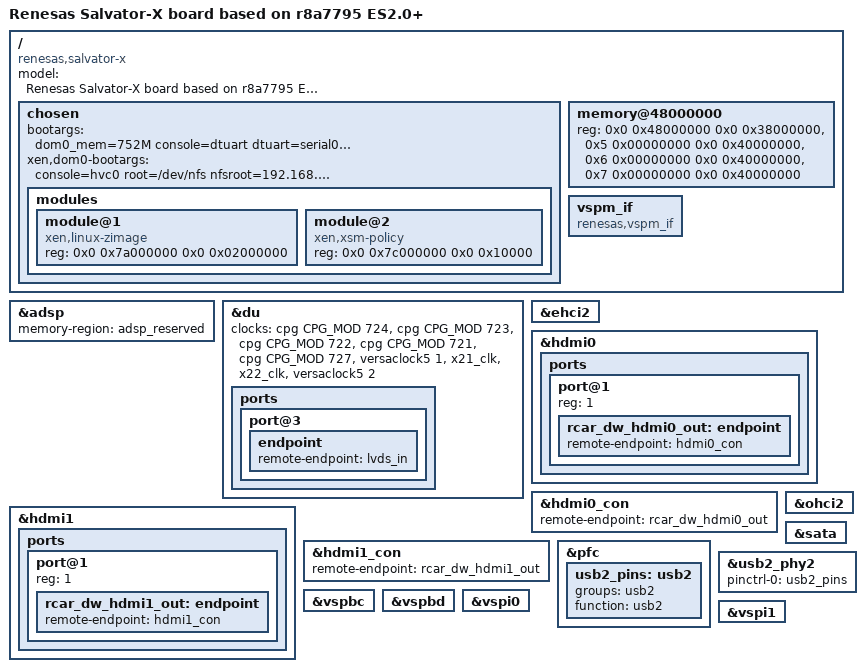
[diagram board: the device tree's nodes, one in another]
/*
 * Device Tree Source for the Salvator-X board
 *
 * Copyright (C) 2015 Renesas Electronics Corp.
 *
 * This file is licensed under the terms of the GNU General Public License
 * version 2.  This program is licensed "as is" without any warranty of any
 * kind, whether express or implied.
 */

/dts-v1/;
#include "r8a7795.dtsi"
#include "salvator-x.dtsi"

/ {
	model = "Renesas Salvator-X board based on r8a7795 ES2.0+";
	compatible = "renesas,salvator-x", "renesas,r8a7795";

	chosen {
		bootargs = "dom0_mem=752M console=dtuart dtuart=serial0 dom0_max_vcpus=4 bootscrub=0 flask_enforcing=1 loglvl=all";
		xen,dom0-bootargs = "console=hvc0 root=/dev/nfs nfsroot=192.168.1.100:/srv/dom0 ip=192.168.1.10 rw rootwait rootfstype=ext4 ignore_loglevel cma=128M";
		modules {
			#address-cells = <2>;
			#size-cells = <2>;
			module@1 {
				compatible = "xen,linux-zimage", "xen,multiboot-module";
				reg = <0x0 0x7a000000 0x0 0x02000000>;
			};
			module@2 {
				compatible = "xen,xsm-policy", "xen,multiboot-module";
				reg = <0x0 0x7c000000 0x0 0x10000>;
			};
		};
	};

	memory@48000000 {
		device_type = "memory";
		/* first 128MB is reserved for secure area. */
		reg = <0x0 0x48000000 0x0 0x38000000>,
		      <0x5 0x00000000 0x0 0x40000000>,
		      <0x6 0x00000000 0x0 0x40000000>,
		      <0x7 0x00000000 0x0 0x40000000>;
	};


	vspm_if {
		compatible = "renesas,vspm_if";
	};
};

&adsp {
	status = "okay";
	memory-region = <&adsp_reserved>;
};

&du {
	clocks = <&cpg CPG_MOD 724>,
		 <&cpg CPG_MOD 723>,
		 <&cpg CPG_MOD 722>,
		 <&cpg CPG_MOD 721>,
		 <&cpg CPG_MOD 727>,
		 <&versaclock5 1>,
		 <&x21_clk>,
		 <&x22_clk>,
		 <&versaclock5 2>;
	clock-names = "du.0", "du.1", "du.2", "du.3", "lvds.0",
		      "dclkin.0", "dclkin.1", "dclkin.2", "dclkin.3";

	ports {
		port@3 {
			endpoint {
				remote-endpoint = <&lvds_in>;
			};
		};
	};
};

&ehci2 {
	status = "okay";
};

&hdmi0 {
	status = "okay";

	ports {
		port@1 {
			reg = <1>;
			rcar_dw_hdmi0_out: endpoint {
				remote-endpoint = <&hdmi0_con>;
			};
		};
	};
};

&hdmi0_con {
	remote-endpoint = <&rcar_dw_hdmi0_out>;
};

&hdmi1 {
	status = "okay";

	ports {
		port@1 {
			reg = <1>;
			rcar_dw_hdmi1_out: endpoint {
				remote-endpoint = <&hdmi1_con>;
			};
		};
	};
};

&hdmi1_con {
	remote-endpoint = <&rcar_dw_hdmi1_out>;
};

&ohci2 {
	status = "okay";
};

&pfc {
	usb2_pins: usb2 {
		groups = "usb2";
		function = "usb2";
	};
};

&sata {
	status = "okay";
};

&usb2_phy2 {
	pinctrl-0 = <&usb2_pins>;
	pinctrl-names = "default";

	status = "okay";
};

&vspbc {
	status = "okay";
};

&vspbd {
	status = "okay";
};

&vspi0 {
	status = "okay";
};

&vspi1 {
	status = "okay";
};
